# N32WB03X register map
Vendor: Nationstech Ltd.; File version: 1.0
Registers are 32-bit, read-write, reset 0x0 unless marked. A register's access mark holds for its fields unless they carry their own. Offsets are from the block's base; [hi:lo] are bit positions; {n}, {i} and the like mark numbered series.

## EXTI — external interrupt/event controller
Base 0x40010400
0x00 EXTI_IMASK
  [13:0] IMASK
0x04 EXTI_EMASK
  [13:0] EMASK
0x08 EXTI_RT_CFG
  [13:0] RT_CFG
0x0C EXTI_FT_CFG
  [13:0] FT_CFG
0x10 EXTI_SWIE
  [13:0] SWIE
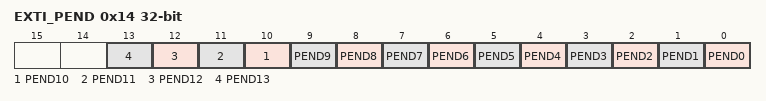
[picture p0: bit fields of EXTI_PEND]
0x14 EXTI_PEND
  [n] PEND{n} (n=0..13)

## GPIOA — General purpose I/O
Base 0x40010800
Same registers: GPIOB 0x40010C00
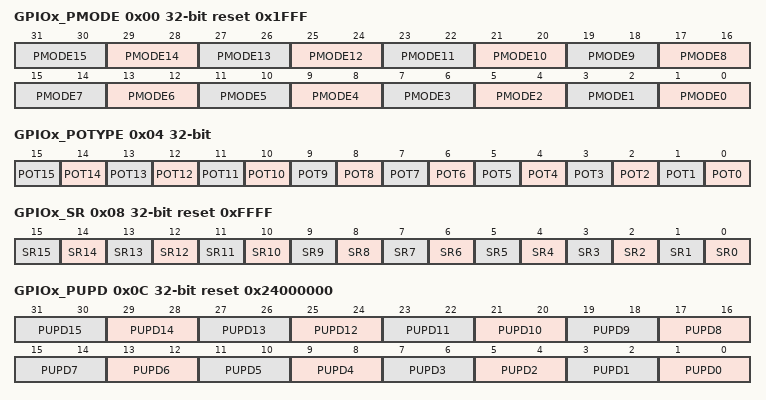
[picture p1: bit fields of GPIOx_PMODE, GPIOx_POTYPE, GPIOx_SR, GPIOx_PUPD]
0x00 GPIOx_PMODE reset 0x1FFF
  [2n+1:2n] PMODE{n} (n=0..15)
0x04 GPIOx_POTYPE
  [n] POT{n} (n=0..15)
0x08 GPIOx_SR reset 0xFFFF
  [n] SR{n} (n=0..15)
0x0C GPIOx_PUPD reset 0x24000000
  [2n+1:2n] PUPD{n} (n=0..15)
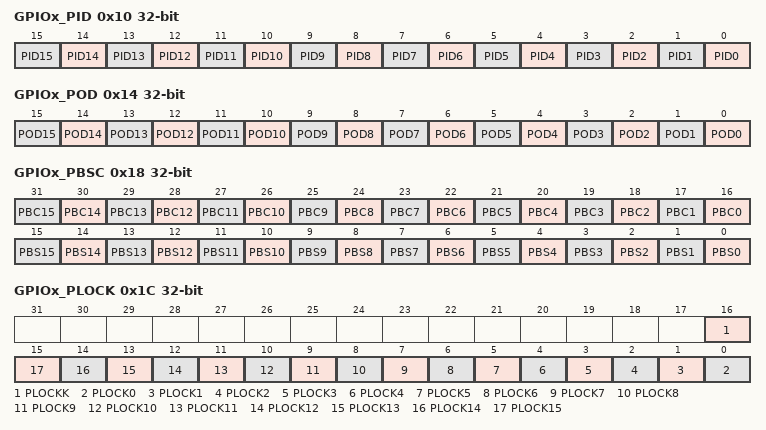
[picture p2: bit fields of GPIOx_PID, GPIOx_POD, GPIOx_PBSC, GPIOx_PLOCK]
0x10 GPIOx_PID
  [n] PID{n} (n=0..15)
0x14 GPIOx_POD
  [n] POD{n} (n=0..15)
0x18 GPIOx_PBSC
  [n+16] PBC{n} (n=0..15), [n] PBS{n} (n=0..15)
0x1C GPIOx_PLOCK
  [16] PLOCKK, [n] PLOCK{n} (n=0..15)
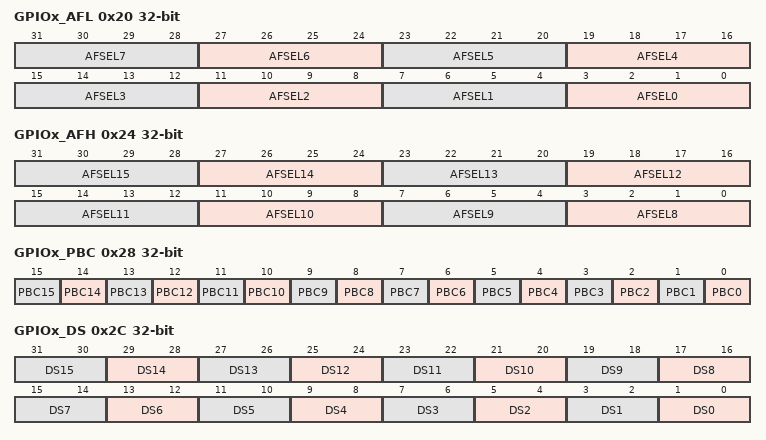
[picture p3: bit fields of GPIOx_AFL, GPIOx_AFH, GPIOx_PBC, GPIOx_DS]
0x20 GPIOx_AFL
  [4n+3:4n] AFSEL{n} (n=0..7)
0x24 GPIOx_AFH
  [4n-29:4n-32] AFSEL{n} (n=8..15)
0x28 GPIOx_PBC
  [n] PBC{n} (n=0..15)
0x2C GPIOx_DS (reset mask 0xFFFFFFF)
  [2n+1:2n] DS{n} (n=0..15)

## AFIO — Alternate function I/O
Base 0x40010000
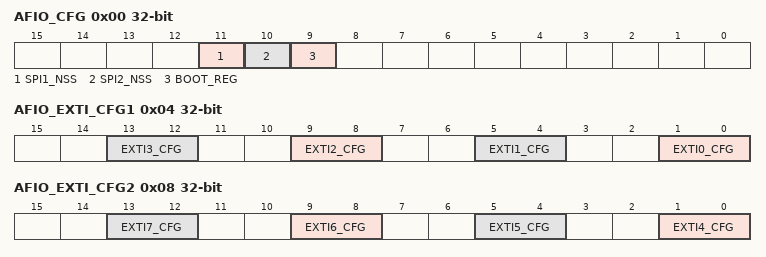
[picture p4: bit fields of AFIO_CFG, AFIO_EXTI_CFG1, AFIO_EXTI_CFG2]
0x00 AFIO_CFG (reset mask 0xC00)
  [11] SPI1_NSS, [10] SPI2_NSS, [9] BOOT_REG
0x04 AFIO_EXTI_CFG1
  [4n+1:4n] EXTI{n}_CFG (n=0..3)
0x08 AFIO_EXTI_CFG2
  [4n-15:4n-16] EXTI{n}_CFG (n=4..7)

## I2C1 — Inter integrated circuit
Base 0x40005400
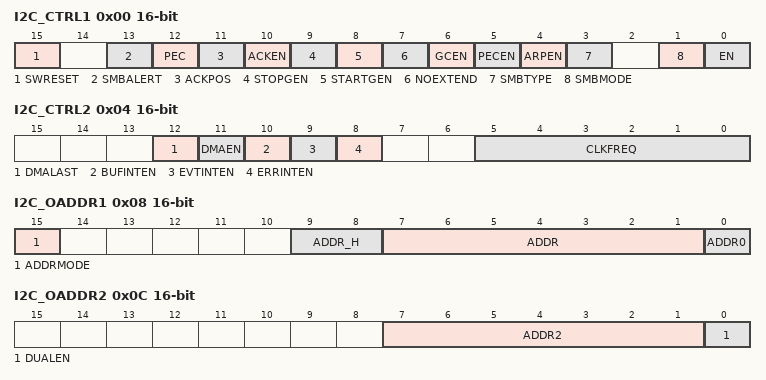
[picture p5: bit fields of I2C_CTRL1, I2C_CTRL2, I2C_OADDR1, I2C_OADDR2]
0x00 I2C_CTRL1 16-bit
  [15] SWRESET, [13] SMBALERT, [12] PEC, [11] ACKPOS, [10] ACKEN, [9] STOPGEN, [8] STARTGEN, [7] NOEXTEND, [6] GCEN, [5] PECEN, [4] ARPEN, [3] SMBTYPE, [1] SMBMODE, [0] EN
0x04 I2C_CTRL2 16-bit
  [12] DMALAST, [11] DMAEN, [10] BUFINTEN, [9] EVTINTEN, [8] ERRINTEN, [5:0] CLKFREQ
0x08 I2C_OADDR1 16-bit
  [15] ADDRMODE, [9:8] ADDR_H, [7:1] ADDR, [0] ADDR0
0x0C I2C_OADDR2 16-bit
  [7:1] ADDR2, [0] DUALEN
0x10 I2C_DAT 16-bit
  [7:0] DATA
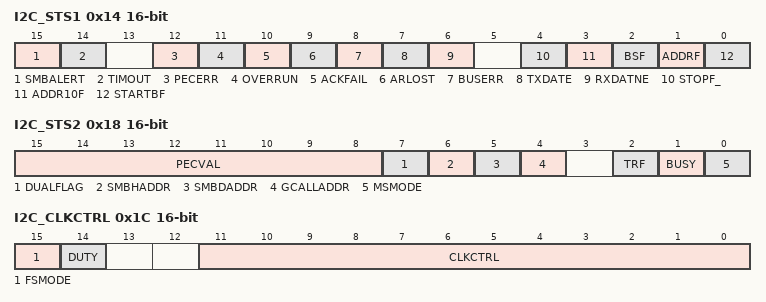
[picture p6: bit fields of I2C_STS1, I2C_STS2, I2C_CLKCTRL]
0x14 I2C_STS1 16-bit
  [15] SMBALERT, [14] TIMOUT, [12] PECERR, [11] OVERRUN, [10] ACKFAIL, [9] ARLOST, [8] BUSERR, [7] TXDATE, [6] RXDATNE, [4] STOPF_, [3] ADDR10F, [2] BSF, [1] ADDRF, [0] STARTBF
0x18 I2C_STS2 16-bit
  [15:8] PECVAL, [7] DUALFLAG, [6] SMBHADDR, [5] SMBDADDR, [4] GCALLADDR, [2] TRF, [1] BUSY, [0] MSMODE
0x1C I2C_CLKCTRL 16-bit
  [15] FSMODE, [14] DUTY, [11:0] CLKCTRL
0x20 I2C_TMRISE 16-bit
  [5:0] TMRISE

## IWDG — Independent watchdog
Base 0x40003000
0x00 IWDG_KEY
  [15:0] KEYV
0x04 IWDG_PREDIV
  [2:0] PD
0x08 IWDG_RELV reset 0xFFF
  [11:0] REL
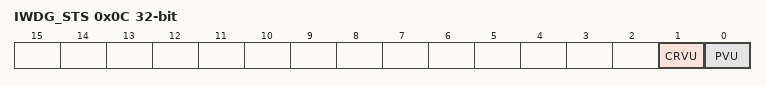
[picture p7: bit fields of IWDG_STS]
0x0C IWDG_STS
  [1] CRVU, [0] PVU

## LPUART1 — Low-power universal asynchronous receiver transmitter
Base 0x40004800
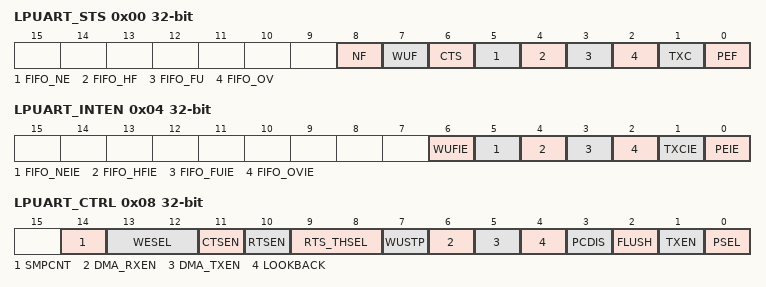
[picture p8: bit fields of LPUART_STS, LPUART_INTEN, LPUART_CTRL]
0x00 LPUART_STS
  [8] NF, [7] WUF, [6] CTS, [5] FIFO_NE, [4] FIFO_HF, [3] FIFO_FU, [2] FIFO_OV, [1] TXC, [0] PEF
0x04 LPUART_INTEN
  [6] WUFIE, [5] FIFO_NEIE, [4] FIFO_HFIE, [3] FIFO_FUIE, [2] FIFO_OVIE, [1] TXCIE, [0] PEIE
0x08 LPUART_CTRL
  [14] SMPCNT, [13:12] WESEL, [11] CTSEN, [10] RTSEN, [9:8] RTS_THSEL, [7] WUSTP, [6] DMA_RXEN, [5] DMA_TXEN, [4] LOOKBACK, [3] PCDIS, [2] FLUSH, [1] TXEN, [0] PSEL
0x0C LPUART_BRCFG1 reset 0x174
  [15:0] INTEGER
0x10 LPUART_DAT
  [7:0] DAT
0x14 LPUART_BRCFG2
  [7:0] DECIMAL
0x18 LPUART_WUDAT

## PWR — Power control
Base 0x40007000
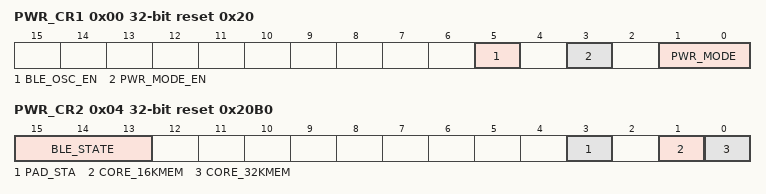
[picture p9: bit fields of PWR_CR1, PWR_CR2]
0x00 PWR_CR1 reset 0x20
  [5] BLE_OSC_EN, [3] PWR_MODE_EN, [1:0] PWR_MODE
0x04 PWR_CR2 reset 0x20B0
  [15:13] BLE_STATE, [3] PAD_STA, [1] CORE_16KMEM, [0] CORE_32KMEM
0x30 VTOR_REG reset 0x20008

## RCC — Reset and clock control
Base 0x40021000
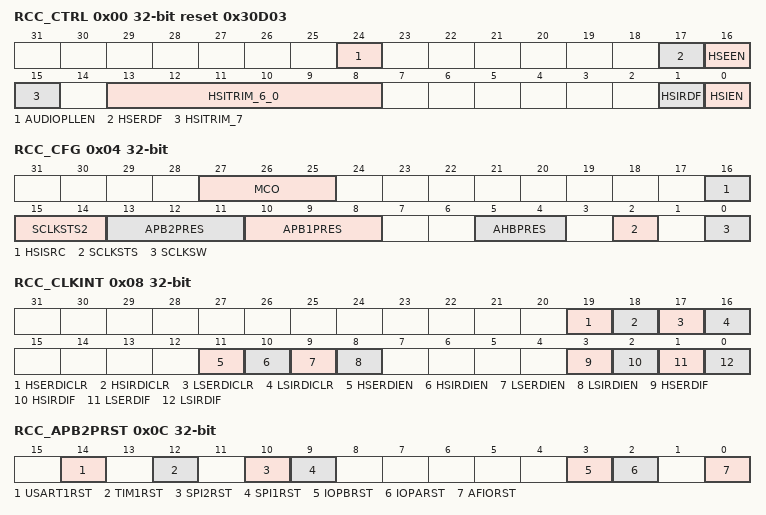
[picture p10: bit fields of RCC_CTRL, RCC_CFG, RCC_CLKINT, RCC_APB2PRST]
0x00 RCC_CTRL reset 0x30D03
  [24] AUDIOPLLEN, [17] HSERDF, [16] HSEEN, [15] HSITRIM_7, [13:8] HSITRIM_6_0, [1] HSIRDF, [0] HSIEN
0x04 RCC_CFG
  [27:25] MCO, [16] HSISRC, [15:14] SCLKSTS2, [13:11] APB2PRES, [10:8] APB1PRES, [5:4] AHBPRES, [2] SCLKSTS, [0] SCLKSW
0x08 RCC_CLKINT
  [19] HSERDICLR, [18] HSIRDICLR, [17] LSERDICLR, [16] LSIRDICLR, [11] HSERDIEN, [10] HSIRDIEN, [9] LSERDIEN, [8] LSIRDIEN, [3] HSERDIF, [2] HSIRDIF, [1] LSERDIF, [0] LSIRDIF
0x0C RCC_APB2PRST
  [14] USART1RST, [12] TIM1RST, [10] SPI2RST, [9] SPI1RST, [3] IOPBRST, [2] IOPARST, [0] AFIORST
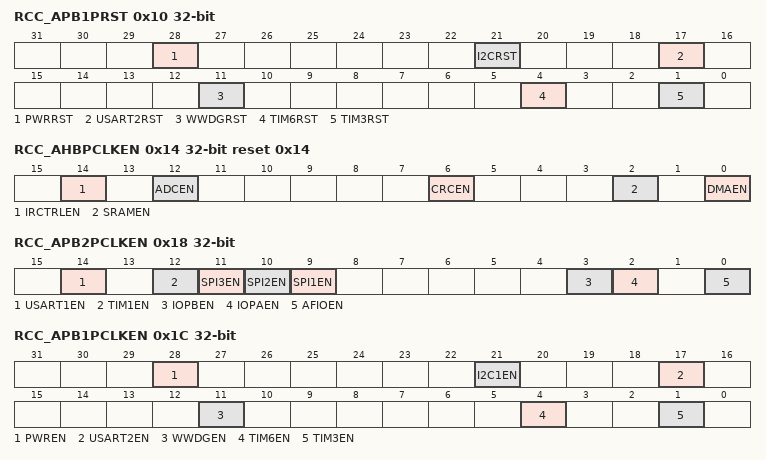
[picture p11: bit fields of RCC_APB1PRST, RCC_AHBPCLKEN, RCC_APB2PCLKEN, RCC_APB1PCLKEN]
0x10 RCC_APB1PRST
  [28] PWRRST, [21] I2CRST, [17] USART2RST, [11] WWDGRST, [4] TIM6RST, [1] TIM3RST
0x14 RCC_AHBPCLKEN reset 0x14
  [14] IRCTRLEN, [12] ADCEN, [6] CRCEN, [2] SRAMEN, [0] DMAEN
0x18 RCC_APB2PCLKEN
  [14] USART1EN, [12] TIM1EN, [11] SPI3EN, [10] SPI2EN, [9] SPI1EN, [3] IOPBEN, [2] IOPAEN, [0] AFIOEN
0x1C RCC_APB1PCLKEN
  [28] PWREN, [21] I2C1EN, [17] USART2EN, [11] WWDGEN, [4] TIM6EN, [1] TIM3EN
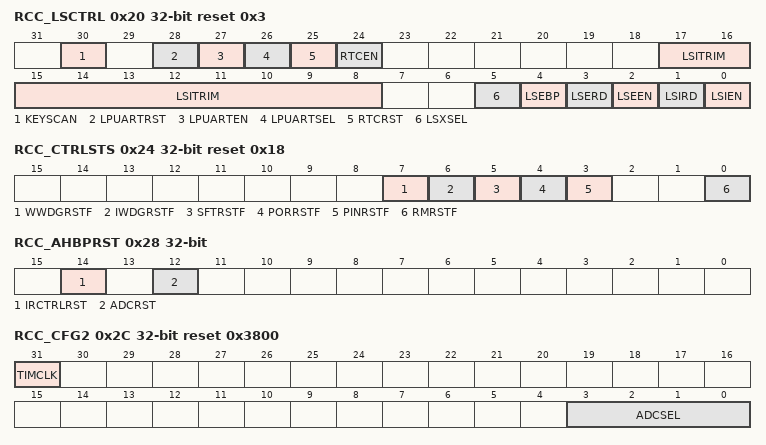
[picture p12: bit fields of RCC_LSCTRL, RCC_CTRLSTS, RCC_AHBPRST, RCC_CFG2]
0x20 RCC_LSCTRL reset 0x3
  [30] KEYSCAN, [28] LPUARTRST, [27] LPUARTEN, [26] LPUARTSEL, [25] RTCRST, [24] RTCEN, [17:8] LSITRIM, [5] LSXSEL, [4] LSEBP, [3] LSERD, [2] LSEEN, [1] LSIRD, [0] LSIEN
0x24 RCC_CTRLSTS reset 0x18
  [7] WWDGRSTF, [6] IWDGRSTF, [5] SFTRSTF, [4] PORRSTF, [3] PINRSTF, [0] RMRSTF
0x28 RCC_AHBPRST
  [14] IRCTRLRST, [12] ADCRST
0x2C RCC_CFG2 reset 0x3800 (reset mask 0x80000010)
  [31] TIMCLK, [3:0] ADCSEL
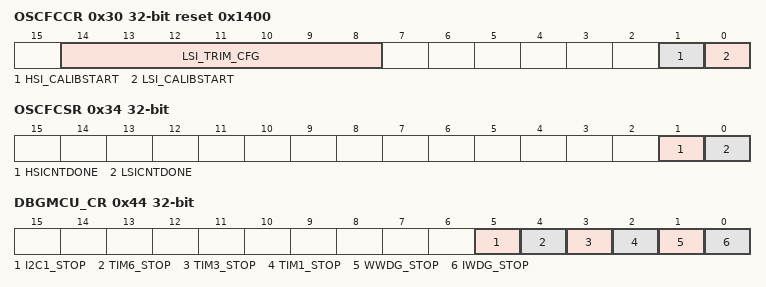
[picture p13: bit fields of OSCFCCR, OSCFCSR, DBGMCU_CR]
0x30 OSCFCCR reset 0x1400
  [14:8] LSI_TRIM_CFG, [1] HSI_CALIBSTART, [0] LSI_CALIBSTART
0x34 OSCFCSR
  [1] HSICNTDONE, [0] LSICNTDONE
0x38 OSCFCLSICNT
  [17:0] LSICNT
0x3C OSCFCHSICNT
  [11:0] HSICNT
0x44 DBGMCU_CR
  [5] I2C1_STOP, [4] TIM6_STOP, [3] TIM3_STOP, [2] TIM1_STOP, [1] WWDG_STOP, [0] IWDG_STOP
